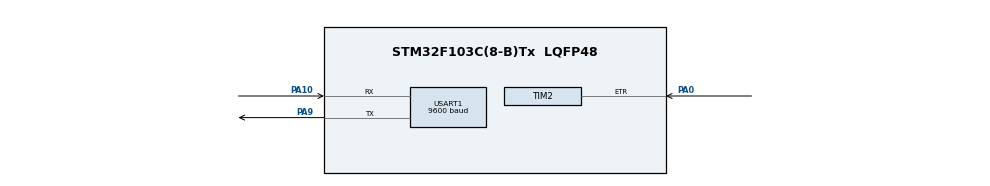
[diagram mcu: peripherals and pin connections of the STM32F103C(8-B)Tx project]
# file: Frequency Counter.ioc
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Mcu.Family=STM32F1
Mcu.Name=STM32F103C(8-B)Tx
Mcu.Package=LQFP48
NVIC.PriorityGroup=NVIC_PRIORITYGROUP_4
NVIC.TIM3_IRQn=true\:0\:0\:false\:false\:true\:true\:true
PA0-WKUP.Signal=S_TIM2_CH1_ETR
PA10.Mode=Asynchronous
PA10.Signal=USART1_RX
PA13.Mode=Serial_Wire
PA13.Signal=SYS_JTMS-SWDIO
PA14.Mode=Serial_Wire
PA14.Signal=SYS_JTCK-SWCLK
PA9.Mode=Asynchronous
PA9.Signal=USART1_TX
PD0-OSC_IN.Mode=HSE-External-Oscillator
PD0-OSC_IN.Signal=RCC_OSC_IN
PD1-OSC_OUT.Mode=HSE-External-Oscillator
PD1-OSC_OUT.Signal=RCC_OSC_OUT
ProjectManager.HeapSize=0x200
ProjectManager.StackSize=0x400
ProjectManager.TargetToolchain=STM32CubeIDE
RCC.APB1Freq_Value=8000000
RCC.APB2Freq_Value=8000000
SH.S_TIM2_CH1_ETR.0=TIM2_ETR,ClockSourceETR_Mode2
TIM2.AutoReloadPreload=TIM_AUTORELOAD_PRELOAD_ENABLE
TIM3.AutoReloadPreload=TIM_AUTORELOAD_PRELOAD_ENABLE
TIM3.Period=36000
TIM3.Prescaler=100
USART1.BaudRate=9600
USART1.VirtualMode=VM_ASYNC
VP_TIM3_VS_ClockSourceINT.Mode=Internal
board=custom

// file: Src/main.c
/* USER CODE BEGIN Header */
/**
  ******************************************************************************
  * @file           : main.c
  * @brief          : Main program body
  ******************************************************************************
  * @attention
  *
  * Copyright (c) 2022 STMicroelectronics.
  * All rights reserved.
  *
  * This software is licensed under terms that can be found in the LICENSE file
  * in the root directory of this software component.
  * If no LICENSE file comes with this software, it is provided AS-IS.
  *
  ******************************************************************************
  */
/* USER CODE END Header */
#include "main.h"

TIM_HandleTypeDef htim2;
TIM_HandleTypeDef htim3;

UART_HandleTypeDef huart1;

/* USER CODE BEGIN PV */
uint32_t pulse_counts = 0 ;
uint32_t wave_freq = 0 ;
uint8_t MSG[20] = {'\0'};
/* USER CODE END PV */

void SystemClock_Config(void);
static void MX_GPIO_Init(void);
static void MX_TIM2_Init(void);
static void MX_TIM3_Init(void);
static void MX_USART1_UART_Init(void);

int main(void)
{

  /* MCU Configuration--------------------------------------------------------*/

  /* Reset of all peripherals, Initializes the Flash interface and the Systick. */
  HAL_Init();

  /* Configure the system clock */
  SystemClock_Config();

  /* Initialize all configured peripherals */
  MX_GPIO_Init();
  MX_TIM2_Init();
  MX_TIM3_Init();
  MX_USART1_UART_Init();
  /* USER CODE BEGIN 2 */
  HAL_TIM_Base_Start_IT(&htim3);
  HAL_TIM_Base_Start(&htim2);
  /* USER CODE END 2 */

  /* Infinite loop */
  while (1)
  {

  }
}

void SystemClock_Config(void)
{
  RCC_OscInitTypeDef RCC_OscInitStruct = {0};
  RCC_ClkInitTypeDef RCC_ClkInitStruct = {0};

  /** Initializes the RCC Oscillators according to the specified parameters
  * in the RCC_OscInitTypeDef structure.
  */
  RCC_OscInitStruct.OscillatorType = RCC_OSCILLATORTYPE_HSI;
  RCC_OscInitStruct.HSIState = RCC_HSI_ON;
  RCC_OscInitStruct.HSICalibrationValue = RCC_HSICALIBRATION_DEFAULT;
  RCC_OscInitStruct.PLL.PLLState = RCC_PLL_NONE;
  if (HAL_RCC_OscConfig(&RCC_OscInitStruct) != HAL_OK)
  {
    Error_Handler();
  }
  /** Initializes the CPU, AHB and APB buses clocks
  */
  RCC_ClkInitStruct.ClockType = RCC_CLOCKTYPE_HCLK|RCC_CLOCKTYPE_SYSCLK
                              |RCC_CLOCKTYPE_PCLK1|RCC_CLOCKTYPE_PCLK2;
  RCC_ClkInitStruct.SYSCLKSource = RCC_SYSCLKSOURCE_HSI;
  RCC_ClkInitStruct.AHBCLKDivider = RCC_SYSCLK_DIV1;
  RCC_ClkInitStruct.APB1CLKDivider = RCC_HCLK_DIV1;
  RCC_ClkInitStruct.APB2CLKDivider = RCC_HCLK_DIV1;

  if (HAL_RCC_ClockConfig(&RCC_ClkInitStruct, FLASH_LATENCY_0) != HAL_OK)
  {
    Error_Handler();
  }
}

static void MX_TIM2_Init(void)
{

  TIM_ClockConfigTypeDef sClockSourceConfig = {0};
  TIM_MasterConfigTypeDef sMasterConfig = {0};

  htim2.Instance = TIM2;
  htim2.Init.Prescaler = 0;
  htim2.Init.CounterMode = TIM_COUNTERMODE_UP;
  htim2.Init.Period = 65535;
  htim2.Init.ClockDivision = TIM_CLOCKDIVISION_DIV1;
  htim2.Init.AutoReloadPreload = TIM_AUTORELOAD_PRELOAD_ENABLE;
  if (HAL_TIM_Base_Init(&htim2) != HAL_OK)
  {
    Error_Handler();
  }
  sClockSourceConfig.ClockSource = TIM_CLOCKSOURCE_ETRMODE2;
  sClockSourceConfig.ClockPolarity = TIM_CLOCKPOLARITY_NONINVERTED;
  sClockSourceConfig.ClockPrescaler = TIM_CLOCKPRESCALER_DIV1;
  sClockSourceConfig.ClockFilter = 0;
  if (HAL_TIM_ConfigClockSource(&htim2, &sClockSourceConfig) != HAL_OK)
  {
    Error_Handler();
  }
  sMasterConfig.MasterOutputTrigger = TIM_TRGO_RESET;
  sMasterConfig.MasterSlaveMode = TIM_MASTERSLAVEMODE_DISABLE;
  if (HAL_TIMEx_MasterConfigSynchronization(&htim2, &sMasterConfig) != HAL_OK)
  {
    Error_Handler();
  }

}

static void MX_TIM3_Init(void)
{

  TIM_ClockConfigTypeDef sClockSourceConfig = {0};
  TIM_MasterConfigTypeDef sMasterConfig = {0};

  htim3.Instance = TIM3;
  htim3.Init.Prescaler = 100;
  htim3.Init.CounterMode = TIM_COUNTERMODE_UP;
  htim3.Init.Period = 36000;
  htim3.Init.ClockDivision = TIM_CLOCKDIVISION_DIV1;
  htim3.Init.AutoReloadPreload = TIM_AUTORELOAD_PRELOAD_ENABLE;
  if (HAL_TIM_Base_Init(&htim3) != HAL_OK)
  {
    Error_Handler();
  }
  sClockSourceConfig.ClockSource = TIM_CLOCKSOURCE_INTERNAL;
  if (HAL_TIM_ConfigClockSource(&htim3, &sClockSourceConfig) != HAL_OK)
  {
    Error_Handler();
  }
  sMasterConfig.MasterOutputTrigger = TIM_TRGO_RESET;
  sMasterConfig.MasterSlaveMode = TIM_MASTERSLAVEMODE_DISABLE;
  if (HAL_TIMEx_MasterConfigSynchronization(&htim3, &sMasterConfig) != HAL_OK)
  {
    Error_Handler();
  }

}

static void MX_USART1_UART_Init(void)
{

  huart1.Instance = USART1;
  huart1.Init.BaudRate = 9600;
  huart1.Init.WordLength = UART_WORDLENGTH_8B;
  huart1.Init.StopBits = UART_STOPBITS_1;
  huart1.Init.Parity = UART_PARITY_NONE;
  huart1.Init.Mode = UART_MODE_TX_RX;
  huart1.Init.HwFlowCtl = UART_HWCONTROL_NONE;
  huart1.Init.OverSampling = UART_OVERSAMPLING_16;
  if (HAL_UART_Init(&huart1) != HAL_OK)
  {
    Error_Handler();
  }

}

static void MX_GPIO_Init(void)
{

  /* GPIO Ports Clock Enable */
  __HAL_RCC_GPIOD_CLK_ENABLE();
  __HAL_RCC_GPIOA_CLK_ENABLE();

}

/* USER CODE BEGIN 4 */
//calculate frequency using number of samples during 0.05s
//this is only valid for frequencies < 1.31(65536*20)MHz
void HAL_TIM_PeriodElapsedCallback(TIM_HandleTypeDef* htim)
{
    if(htim->Instance == TIM3)
    {
        pulse_counts = TIM2->CNT;
        wave_freq = pulse_counts * 20;
        sprintf(MSG, "Frequency = %d Hz\n\r", wave_freq);
        HAL_UART_Transmit(&huart1, MSG, sizeof(MSG), 100);
        TIM3->CNT = 0;
        TIM2->CNT = 0;
    }
}
/* USER CODE END 4 */

void Error_Handler(void)
{
  __disable_irq();
  while (1)
  {
  }
}
